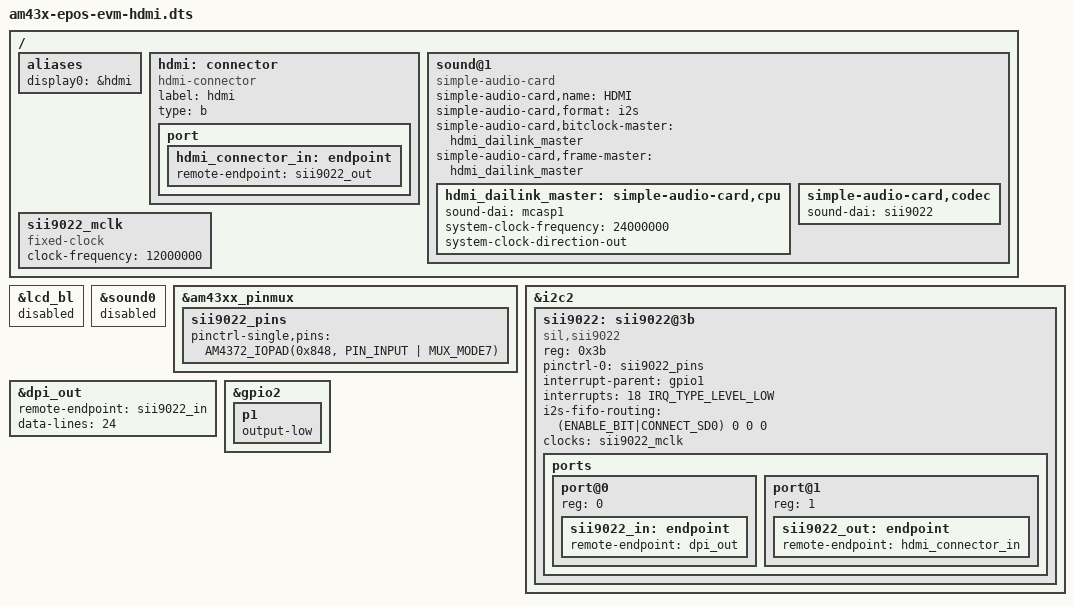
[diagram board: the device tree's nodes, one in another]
// SPDX-License-Identifier: GPL-2.0
/*
 * Copyright (C) 2018 Texas Instruments Incorporated - http://www.ti.com/
 */

/* AM43x EPOS EVM with HDMI output */

#include "am43x-epos-evm.dts"

/delete-node/ &lcd0;

#include <dt-bindings/sound/sii902x-audio.h>

/ {
	aliases {
		display0 = &hdmi;
	};

	hdmi: connector {
		compatible = "hdmi-connector";
		label = "hdmi";

		type = "b";

		port {
			hdmi_connector_in: endpoint {
				remote-endpoint = <&sii9022_out>;
			};
		};
	};

	sound@1 {
		compatible = "simple-audio-card";
		simple-audio-card,name = "HDMI";
		simple-audio-card,format = "i2s";
		simple-audio-card,bitclock-master = <&hdmi_dailink_master>;
		simple-audio-card,frame-master = <&hdmi_dailink_master>;
		hdmi_dailink_master: simple-audio-card,cpu {
			sound-dai = <&mcasp1>;
			system-clock-frequency = <24000000>;
			system-clock-direction-out;
		};

		simple-audio-card,codec {
			sound-dai = <&sii9022>;
		};
	};

	sii9022_mclk: sii9022_mclk {
		compatible = "fixed-clock";
		#clock-cells = <0>;
		clock-frequency = <12000000>;
	};
};

&lcd_bl {
	status = "disabled";
};

&sound0 {
	status = "disabled";
};

&am43xx_pinmux {
	sii9022_pins: sii9022_pins {
		pinctrl-single,pins = <
			AM4372_IOPAD(0x848, PIN_INPUT | MUX_MODE7)	/* gpmc_a2.gpio1_18 */
		>;
	};
};

&i2c2 {
	sii9022: sii9022@3b {
		#sound-dai-cells = <0>;
		compatible = "sil,sii9022";
		reg = <0x3b>;

		pinctrl-names = "default";
		pinctrl-0 = <&sii9022_pins>;

		interrupt-parent = <&gpio1>;
		interrupts = <18 IRQ_TYPE_LEVEL_LOW>;

		i2s-fifo-routing = <
			(ENABLE_BIT|CONNECT_SD0)
			0
			0
			0
		>;
		clocks = <&sii9022_mclk>;
		clock-names = "mclk";

		ports {
			#address-cells = <1>;
			#size-cells = <0>;

			port@0 {
				reg = <0>;

				sii9022_in: endpoint {
					remote-endpoint = <&dpi_out>;
				};
			};

			port@1 {
				reg = <1>;

				sii9022_out: endpoint {
					remote-endpoint = <&hdmi_connector_in>;
				};
			};
		};
	};
};

&dpi_out {
	remote-endpoint = <&sii9022_in>;
	data-lines = <24>;
};

/* Override SelLCDorHDMI from am43x-epos-evm.dts to select HDMI */
&gpio2 {
	p1 {
		output-low;
	};
};
